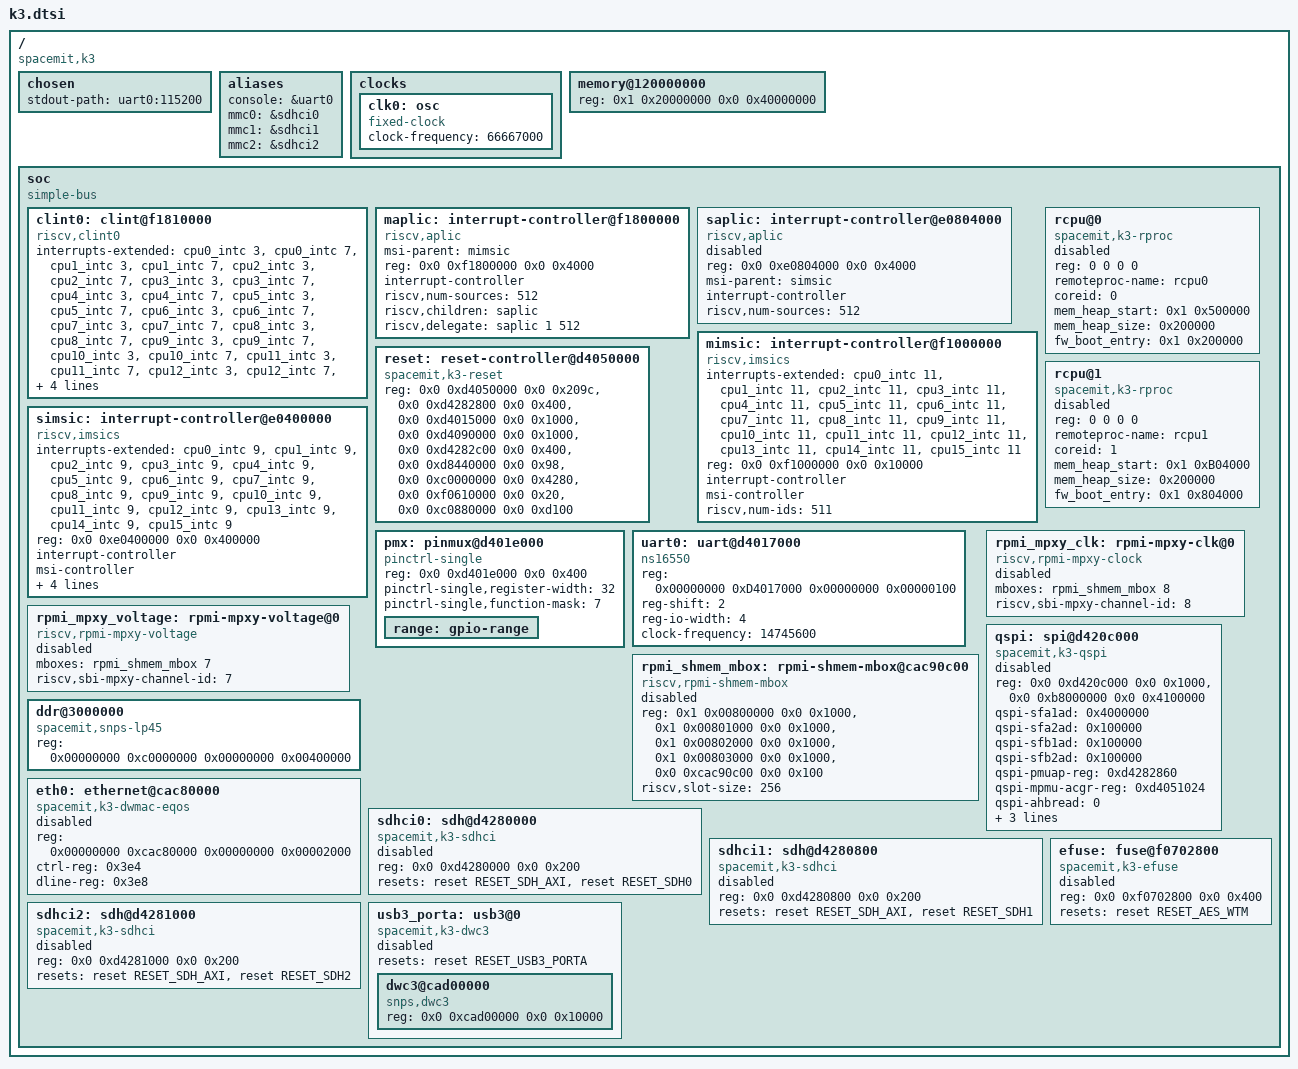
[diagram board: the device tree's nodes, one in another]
// SPDX-License-Identifier: GPL-2.0
/*
 * finch board's base device tree configure.
 *
 * Copyright (C) 2025 SPACEMIT Micro Limited
 */

/dts-v1/;

#include <config.h>
#include "k3-cpus.dtsi"
#include <dt-bindings/reset/reset-spacemit-k3.h>

/ {
	#address-cells = <2>;
	#size-cells = <2>;
	compatible = "spacemit,k3";

	chosen {
		stdout-path = "uart0:115200";
	};

	aliases {
		console = &uart0;
		mmc0 = &sdhci0;
		mmc1 = &sdhci1;
		mmc2 = &sdhci2;
	};

	clocks {
		clk0: osc {
			compatible = "fixed-clock";
			#clock-cells = <0>;
			clock-frequency = <66667000>;
		};
	};

	memory@120000000 {
		u-boot,dm-spl;
		device_type = "memory";
		reg = <0x1 0x20000000 0x0 0x40000000>;
	};

	soc {
		u-boot,dm-spl;
		#address-cells = <2>;
		#size-cells = <2>;
		compatible = "simple-bus";
		ranges;

		clint0: clint@f1810000 {
			compatible = "riscv,clint0";
			interrupts-extended = <&cpu0_intc  3 &cpu0_intc  7
				&cpu1_intc  3 &cpu1_intc  7
				&cpu2_intc  3 &cpu2_intc  7
				&cpu3_intc  3 &cpu3_intc  7
				&cpu4_intc  3 &cpu4_intc  7
				&cpu5_intc  3 &cpu5_intc  7
				&cpu6_intc  3 &cpu6_intc  7
				&cpu7_intc  3 &cpu7_intc  7
				&cpu8_intc  3 &cpu8_intc  7
				&cpu9_intc  3 &cpu9_intc  7
				&cpu10_intc  3 &cpu10_intc  7
				&cpu11_intc  3 &cpu11_intc  7
				&cpu12_intc  3 &cpu12_intc  7
				&cpu13_intc  3 &cpu13_intc  7
				&cpu14_intc  3 &cpu14_intc  7
				&cpu15_intc  3 &cpu15_intc  7
			>;
			reg = <0x0 0xf1810000 0x0 0x00010000>;
			clint,has-no-64bit-mmio;
		};

		maplic: interrupt-controller@f1800000 {
			compatible = "riscv,aplic";
			msi-parent = <&mimsic>;
			/*aplic config*/
			reg = <0x0 0xf1800000 0x0 0x4000>;
			interrupt-controller;
			#interrupt-cells = <2>;
			/*the number of wired interrupt sources*/
			riscv,num-sources = <512>;
			riscv,children = <&saplic>;
			/*M-mode delegate S-mode*/
			riscv,delegate = <&saplic 1 512>;
			status = "okay";
		};

		saplic: interrupt-controller@e0804000 {
			compatible = "riscv,aplic";
			/*aplic config*/
			reg = <0x0 0xe0804000 0x0 0x4000>;
			msi-parent = <&simsic>;
			#interrupt-cells = <2>;
			interrupt-controller;
			/*the number of wired interrupt sources*/
			riscv,num-sources = <512>;
			status = "disabled";
		};

		mimsic: interrupt-controller@f1000000 {
			compatible = "riscv,imsics";
			interrupts-extended = <&cpu0_intc 11 &cpu1_intc 11
					&cpu2_intc 11 &cpu3_intc 11
					&cpu4_intc 11 &cpu5_intc 11
					&cpu6_intc 11 &cpu7_intc 11
					&cpu8_intc 11 &cpu9_intc 11
					&cpu10_intc 11 &cpu11_intc 11
					&cpu12_intc 11 &cpu13_intc 11
					&cpu14_intc 11 &cpu15_intc 11>;
			reg = <0x0 0xf1000000 0x0 0x10000>;
			interrupt-controller;
			#interrupt-cells = <0>;
			#msi-cells = <0>;
			msi-controller;
			/* Number of interrupt identities: 511 */
			riscv,num-ids = <511>;
			status = "okay";
		};

		simsic: interrupt-controller@e0400000 {
			compatible = "riscv,imsics";
			interrupts-extended = <&cpu0_intc 9 &cpu1_intc 9
				&cpu2_intc 9 &cpu3_intc 9
				&cpu4_intc 9 &cpu5_intc 9
				&cpu6_intc 9 &cpu7_intc 9
				&cpu8_intc 9 &cpu9_intc 9
				&cpu10_intc 9 &cpu11_intc 9
				&cpu12_intc 9 &cpu13_intc 9
				&cpu14_intc 9 &cpu15_intc 9>;
			reg = <0x0 0xe0400000 0x0 0x400000>;
			interrupt-controller;
			#interrupt-cells = <0>;
			#msi-cells = <0>;
			msi-controller;
			/* Number of interrupt identities: 511 */
			riscv,num-ids = <511>;
			/* Number of guest interrupt identities: 511 */
			riscv,num-guest-ids = <511>;
			/* Number of HART index bits: 4 (2^4 = 16 harts) */
			riscv,hart-index-bits = <4>;
			/*
			 * Number of guest index bits: 6
			 *   2^6 = 64 interrupt files
			 *       = 1 s-level interrupt file + 63 vs-level interrupt files
			 *
			 * But on K3,
			 *   X100: only 7 of the 63 vs-level interrupt files are valid.
			 *   A100: no valid vs-level interrupt files.
			 */
			riscv,guest-index-bits = <6>;
			status = "okay";
		};

		reset: reset-controller@d4050000 {
			compatible = "spacemit,k3-reset";
			reg = <0x0 0xd4050000 0x0 0x209c>,
				<0x0 0xd4282800 0x0 0x400>,
				<0x0 0xd4015000 0x0 0x1000>,
				<0x0 0xd4090000 0x0 0x1000>,
				<0x0 0xd4282c00 0x0 0x400>,
				<0x0 0xd8440000 0x0 0x98>,
				<0x0 0xc0000000 0x0 0x4280>,
				<0x0 0xf0610000 0x0 0x20>,
				<0x0 0xc0880000 0x0 0xd100>;
			reg-names = "mpmu", "apmu", "apbc", "apbs", "ciu", "dciu", "ddrc", "apbc2", "rcpu";
			#reset-cells = <1>;
			status = "okay";
		};

		pmx: pinmux@d401e000 {
			compatible = "pinctrl-single";
			reg = <0x0 0xd401e000 0x0 0x400>;
			#address-cells = <1>;
			#size-cells = <1>;
			#pinctrl-cells = <1>;
			#gpio-range-cells = <3>;
			ranges;
			pinctrl-single,register-width = <32>;
			pinctrl-single,function-mask = <7>;

			range: gpio-range {
			#pinctrl-single,gpio-range-cells = <3>;
			};
		};

		uart0: uart@d4017000 {
			u-boot,dm-spl;
			compatible = "ns16550";
			reg = <0x00000000 0xD4017000 0x00000000 0x00000100>;
			reg-shift = <2>;
			reg-io-width = <4>;
			clock-frequency = <14745600>;
		};

		rcpu@0 {
			compatible = "spacemit,k3-rproc";
			u-boot,dm-spl;
			reg = <0 0 0 0>;
			remoteproc-name = "rcpu0";
			coreid = <0>;
			mem_heap_start = <0x1 0x500000>;
			mem_heap_size = <0x200000>;
			fw_boot_entry = <0x1 0x200000>;
			status = "disabled";
		};

		rcpu@1 {
			compatible = "spacemit,k3-rproc";
			u-boot,dm-spl;
			reg = <0 0 0 0>;
			remoteproc-name = "rcpu1";
			coreid = <1>;
			mem_heap_start = <0x1 0xB04000>;
			mem_heap_size = <0x200000>;
			fw_boot_entry = <0x1 0x804000>;
			status = "disabled";
		};

		rpmi_shmem_mbox: rpmi-shmem-mbox@cac90c00 {
			compatible = "riscv,rpmi-shmem-mbox";
			reg = <0x1 0x00800000 0x0 0x1000>,
				<0x1 0x00801000 0x0 0x1000>,
				<0x1 0x00802000 0x0 0x1000>,
				<0x1 0x00803000 0x0 0x1000>,
				<0x0 0xcac90c00 0x0 0x100>;
			reg-names = "a2p-req", "p2a-ack", "p2a-req", "a2p-ack", "db-reg";
			riscv,slot-size = <256>;
			#mbox-cells = <1>;
			status = "disabled";
		};

		rpmi_mpxy_clk: rpmi-mpxy-clk@0 {
			compatible = "riscv,rpmi-mpxy-clock";
			mboxes = <&rpmi_shmem_mbox 8>;
			riscv,sbi-mpxy-channel-id = <8>;
			status = "disabled";
		};

		rpmi_mpxy_voltage: rpmi-mpxy-voltage@0 {
			compatible = "riscv,rpmi-mpxy-voltage";
			mboxes = <&rpmi_shmem_mbox 7>;
			riscv,sbi-mpxy-channel-id = <7>;
			status = "disabled";
		};

		ddr@3000000 {
			u-boot,dm-spl;
			compatible = "spacemit,snps-lp45";
			reg = <0x00000000 0xc0000000 0x00000000 0x00400000>;
			status = "okay";
		};

		eth0: ethernet@cac80000 {
			compatible = "spacemit,k3-dwmac-eqos";
			reg = <0x00000000 0xcac80000 0x00000000 0x00002000>;
			ctrl-reg = <0x3e4>;
			dline-reg = <0x3e8>;
			status = "disabled";
		};

		qspi: spi@d420c000 {
			compatible = "spacemit,k3-qspi";
			#address-cells = <1>;
			#size-cells = <0>;
			reg = <0x0 0xd420c000 0x0 0x1000>,
			      <0x0 0xb8000000 0x0 0x4100000>;
			reg-names = "qspi-base", "qspi-mmap";
			qspi-sfa1ad = <0x4000000>;
			qspi-sfa2ad = <0x100000>;
			qspi-sfb1ad = <0x100000>;
			qspi-sfb2ad = <0x100000>;
			qspi-pmuap-reg = <0xd4282860>;
			qspi-mpmu-acgr-reg = <0xd4051024>;
			qspi-ahbread = <0>;
			qspi-freq = <26500000>;
			qspi-id = <4>;
			resets = <&reset RESET_QSPI>,
				<&reset RESET_QSPI_BUS>;
			reset-names = "qspi_reset", "qspi_bus_reset";
			status = "disabled";
		};

		sdhci0: sdh@d4280000 {
			compatible = "spacemit,k3-sdhci";
			reg = <0x0 0xd4280000 0x0 0x200>;
			resets = <&reset RESET_SDH_AXI>,
				 <&reset RESET_SDH0>;
			reset-names = "sdh_axi", "sdh0";
			status = "disabled";
		};

		sdhci1: sdh@d4280800 {
			compatible = "spacemit,k3-sdhci";
			reg = <0x0 0xd4280800 0x0 0x200>;
			resets = <&reset RESET_SDH_AXI>,
				 <&reset RESET_SDH1>;
			reset-names = "sdh_axi", "sdh1";
			status = "disabled";
		};

		sdhci2: sdh@d4281000 {
			compatible = "spacemit,k3-sdhci";
			reg = <0x0 0xd4281000 0x0 0x200>;
			resets = <&reset RESET_SDH_AXI>,
				 <&reset RESET_SDH2>;
			reset-names = "sdh_axi", "sdh2";
			status = "disabled";
		};

		usb3_porta: usb3@0 {
			compatible = "spacemit,k3-dwc3";
			#address-cells = <2>;
			#size-cells = <2>;
			resets = <&reset RESET_USB3_PORTA>;
			reset-names = "ctl_rst";
			ranges;
			status = "disabled";
			dwc3@cad00000 {
				compatible = "snps,dwc3";
				reg = <0x0 0xcad00000 0x0 0x10000>;
			};
		};

		efuse: fuse@f0702800 {
			compatible = "spacemit,k3-efuse";
			reg = <0x0 0xf0702800 0x0 0x400>;
			resets = <&reset RESET_AES_WTM>;
			reset-names = "aes_reset";
			/*
			clocks = <&ccu CLK_AES_WTM>;
			clock-names = "aes_core_wtm";
			*/
			status = "disabled";
		};
	};

};

